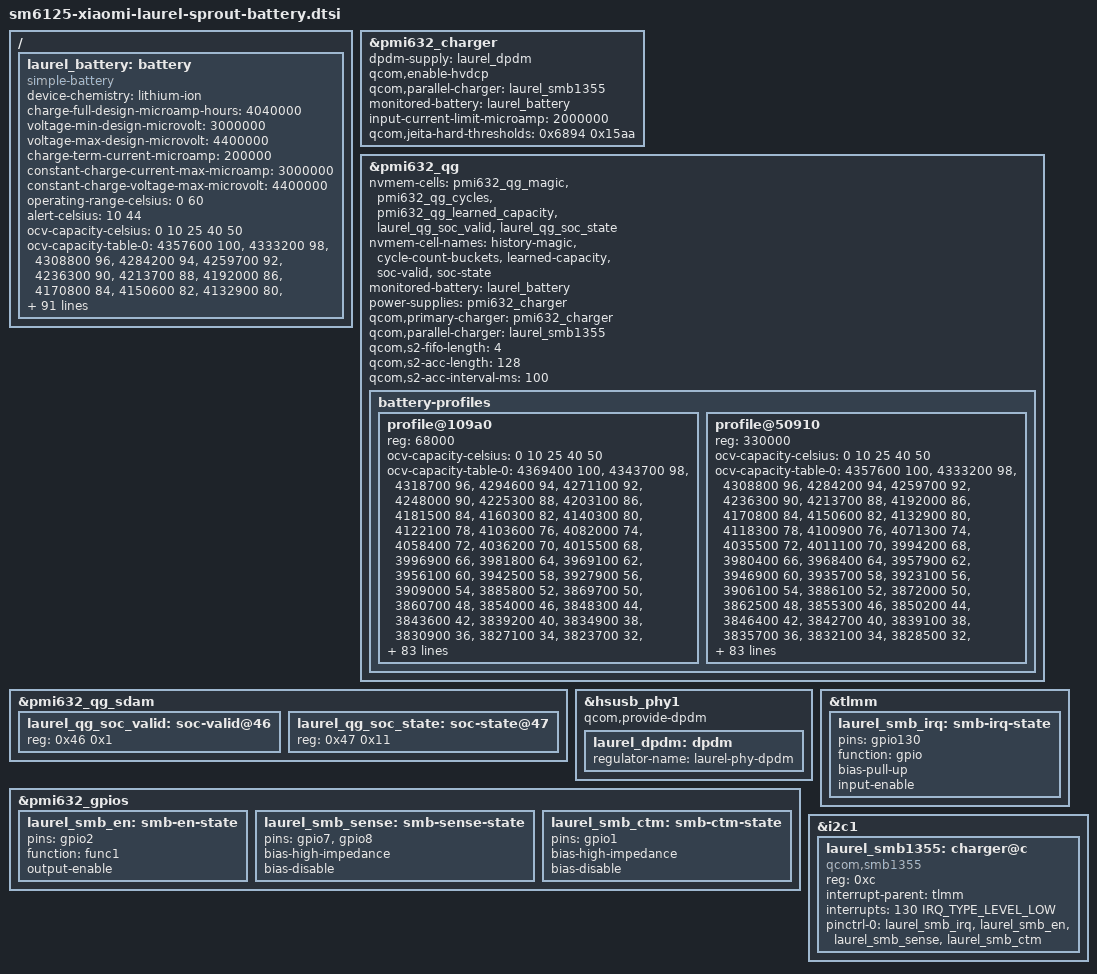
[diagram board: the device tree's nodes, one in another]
// SPDX-License-Identifier: GPL-2.0-only
/*
 * Derived from LineageOS android_kernel_xiaomi_sm6125, revision
 * 77d2912bc00eda19182a95a24bbe23543c792814, Laurel Wingtech fallback
 * battery profile. Original Qualcomm/Wingtech data, not generated curves.
 * See companion kernel Documentation/android/PMIC_BATTERY.md.
 */
/ {
	laurel_battery: battery {
		compatible = "simple-battery";
		device-chemistry = "lithium-ion";
		charge-full-design-microamp-hours = <4040000>;
		voltage-min-design-microvolt = <3000000>;
		voltage-max-design-microvolt = <4400000>;
		charge-term-current-microamp = <200000>;
		constant-charge-current-max-microamp = <3000000>;
		constant-charge-voltage-max-microvolt = <4400000>;
		operating-range-celsius = <0 60>;
		alert-celsius = <10 44>;
		ocv-capacity-celsius = <0 10 25 40 50>;
		/* Stock discharge OCV at 0 C. */
		ocv-capacity-table-0 = <4357600 100>,
			<4333200 98>,
			<4308800 96>,
			<4284200 94>,
			<4259700 92>,
			<4236300 90>,
			<4213700 88>,
			<4192000 86>,
			<4170800 84>,
			<4150600 82>,
			<4132900 80>,
			<4118300 78>,
			<4100900 76>,
			<4071300 74>,
			<4035500 72>,
			<4011100 70>,
			<3994200 68>,
			<3980400 66>,
			<3968400 64>,
			<3957900 62>,
			<3946900 60>,
			<3935700 58>,
			<3923100 56>,
			<3906100 54>,
			<3886100 52>,
			<3872000 50>,
			<3862500 48>,
			<3855300 46>,
			<3850200 44>,
			<3846400 42>,
			<3842700 40>,
			<3839100 38>,
			<3835700 36>,
			<3832100 34>,
			<3828500 32>,
			<3826500 30>,
			<3825900 28>,
			<3825400 26>,
			<3822400 24>,
			<3813100 22>,
			<3801800 20>,
			<3788500 18>,
			<3773200 16>,
			<3755800 14>,
			<3739300 12>,
			<3727700 10>,
			<3724200 9>,
			<3721100 8>,
			<3718300 7>,
			<3713700 6>,
			<3693100 5>,
			<3648900 4>,
			<3590700 3>,
			<3511800 2>,
			<3387200 1>,
			<3000000 0>;
		/* Stock discharge OCV at 10 C. */
		ocv-capacity-table-1 = <4371400 100>,
			<4347700 98>,
			<4321500 96>,
			<4295700 94>,
			<4271400 92>,
			<4247900 90>,
			<4225400 88>,
			<4203700 86>,
			<4182300 84>,
			<4160400 82>,
			<4139400 80>,
			<4121800 78>,
			<4106900 76>,
			<4087700 74>,
			<4055100 72>,
			<4021900 70>,
			<4003100 68>,
			<3989900 66>,
			<3977900 64>,
			<3967700 62>,
			<3956500 60>,
			<3936800 58>,
			<3908900 56>,
			<3889400 54>,
			<3877900 52>,
			<3869000 50>,
			<3861500 48>,
			<3855300 46>,
			<3849400 44>,
			<3843500 42>,
			<3838200 40>,
			<3833200 38>,
			<3828600 36>,
			<3824600 34>,
			<3821400 32>,
			<3818100 30>,
			<3815000 28>,
			<3811800 26>,
			<3806800 24>,
			<3797700 22>,
			<3786500 20>,
			<3774100 18>,
			<3759600 16>,
			<3742000 14>,
			<3729400 12>,
			<3720800 10>,
			<3717300 9>,
			<3715000 8>,
			<3712400 7>,
			<3708300 6>,
			<3686200 5>,
			<3642300 4>,
			<3584200 3>,
			<3504800 2>,
			<3380500 1>,
			<3000000 0>;
		/* Stock discharge OCV at 25 C. */
		ocv-capacity-table-2 = <4382500 100>,
			<4359800 98>,
			<4335600 96>,
			<4310700 94>,
			<4286000 92>,
			<4261900 90>,
			<4238200 88>,
			<4214800 86>,
			<4191800 84>,
			<4169400 82>,
			<4146800 80>,
			<4125600 78>,
			<4107900 76>,
			<4092200 74>,
			<4071100 72>,
			<4038700 70>,
			<4010300 68>,
			<3995800 66>,
			<3984800 64>,
			<3971800 62>,
			<3957300 60>,
			<3940500 58>,
			<3916700 56>,
			<3892200 54>,
			<3876900 52>,
			<3865800 50>,
			<3855900 48>,
			<3846400 46>,
			<3837900 44>,
			<3830400 42>,
			<3823900 40>,
			<3818200 38>,
			<3813300 36>,
			<3809000 34>,
			<3805400 32>,
			<3802000 30>,
			<3798500 28>,
			<3795000 26>,
			<3790400 24>,
			<3782500 22>,
			<3772100 20>,
			<3760500 18>,
			<3746900 16>,
			<3731100 14>,
			<3716600 12>,
			<3707100 10>,
			<3704400 9>,
			<3703100 8>,
			<3701500 7>,
			<3697200 6>,
			<3673900 5>,
			<3630600 4>,
			<3572600 3>,
			<3493400 2>,
			<3370200 1>,
			<3000000 0>;
		/* Stock discharge OCV at 40 C. */
		ocv-capacity-table-3 = <4385300 100>,
			<4361200 98>,
			<4337800 96>,
			<4314000 94>,
			<4289900 92>,
			<4266100 90>,
			<4242500 88>,
			<4219000 86>,
			<4195800 84>,
			<4172800 82>,
			<4149900 80>,
			<4127500 78>,
			<4106700 76>,
			<4087400 74>,
			<4067100 72>,
			<4043600 70>,
			<4020600 68>,
			<4003300 66>,
			<3988800 64>,
			<3973900 62>,
			<3958800 60>,
			<3942000 58>,
			<3919500 56>,
			<3894600 54>,
			<3877400 52>,
			<3865100 50>,
			<3854500 48>,
			<3844500 46>,
			<3835500 44>,
			<3827400 42>,
			<3820100 40>,
			<3813500 38>,
			<3807900 36>,
			<3802700 34>,
			<3798200 32>,
			<3794100 30>,
			<3789600 28>,
			<3785000 26>,
			<3779200 24>,
			<3771000 22>,
			<3760700 20>,
			<3749300 18>,
			<3736000 16>,
			<3720500 14>,
			<3706300 12>,
			<3697600 10>,
			<3695300 9>,
			<3693700 8>,
			<3692000 7>,
			<3687000 6>,
			<3662100 5>,
			<3618700 4>,
			<3561200 3>,
			<3482900 2>,
			<3362200 1>,
			<3000000 0>;
		/* Stock discharge OCV at 50 C. */
		ocv-capacity-table-4 = <4385700 100>,
			<4361300 98>,
			<4338200 96>,
			<4314900 94>,
			<4291300 92>,
			<4267800 90>,
			<4244300 88>,
			<4220900 86>,
			<4197700 84>,
			<4174600 82>,
			<4151700 80>,
			<4129300 78>,
			<4107300 76>,
			<4086000 74>,
			<4065200 72>,
			<4045000 70>,
			<4025500 68>,
			<4007300 66>,
			<3990100 64>,
			<3973600 62>,
			<3958600 60>,
			<3942600 58>,
			<3920800 56>,
			<3895700 54>,
			<3877800 52>,
			<3865400 50>,
			<3854600 48>,
			<3844300 46>,
			<3834900 44>,
			<3826400 42>,
			<3818900 40>,
			<3812100 38>,
			<3806100 36>,
			<3800500 34>,
			<3795100 32>,
			<3790000 30>,
			<3784600 28>,
			<3779200 26>,
			<3772600 24>,
			<3763900 22>,
			<3753300 20>,
			<3741700 18>,
			<3728600 16>,
			<3713200 14>,
			<3699200 12>,
			<3691700 10>,
			<3689300 9>,
			<3687400 8>,
			<3685900 7>,
			<3679800 6>,
			<3652700 5>,
			<3608600 4>,
			<3550800 3>,
			<3471400 2>,
			<3348700 1>,
			<3000000 0>;
	};
};

&pmi632_charger {
	dpdm-supply = <&laurel_dpdm>;
	qcom,enable-hvdcp;
	qcom,parallel-charger = <&laurel_smb1355>;
	status = "okay";
	monitored-battery = <&laurel_battery>;
	input-current-limit-microamp = <2000000>;
	/* Stock hard comparator codes: cold 0 C, hot 60 C. */
	qcom,jeita-hard-thresholds = <0x6894 0x15aa>;
};

&pmi632_qg {
	status = "okay";
	nvmem-cells = <&pmi632_qg_magic>, <&pmi632_qg_cycles>,
		      <&pmi632_qg_learned_capacity>, <&laurel_qg_soc_valid>,
		      <&laurel_qg_soc_state>;
	nvmem-cell-names = "history-magic", "cycle-count-buckets", "learned-capacity",
			   "soc-valid", "soc-state";
	monitored-battery = <&laurel_battery>;
	/* Optional secondary failure must not defer the battery gauge. The
	 * primary notifies after changing the secondary; QG reads that state.
	 */
	power-supplies = <&pmi632_charger>;
	qcom,primary-charger = <&pmi632_charger>;
	qcom,parallel-charger = <&laurel_smb1355>;
	qcom,s2-fifo-length = <4>;
	qcom,s2-acc-length = <128>;
	qcom,s2-acc-interval-ms = <100>;
};

&pmi632_qg_sdam {
	status = "okay";
	/delete-property/ read-only;
	/* LineageOS QG shutdown fields. Cycle/FCC/ESR/PBS cells stay untouched. */
	laurel_qg_soc_valid: soc-valid@46 {
		reg = <0x46 0x1>;
	};
	laurel_qg_soc_state: soc-state@47 {
		reg = <0x47 0x11>;
	};
};

/* Supplier OCV curves are selected by the physical 100k-pullup ID ADC. */
&pmi632_qg {
	battery-profiles {
		#address-cells = <1>;
		#size-cells = <0>;
		/* Stock Sunwoda profile, battery ID 68 kohm. */
		profile@109a0 {
			reg = <68000>;
			ocv-capacity-celsius = <0 10 25 40 50>;
			ocv-capacity-table-0 = <4369400 100>,
				<4343700 98>,
				<4318700 96>,
				<4294600 94>,
				<4271100 92>,
				<4248000 90>,
				<4225300 88>,
				<4203100 86>,
				<4181500 84>,
				<4160300 82>,
				<4140300 80>,
				<4122100 78>,
				<4103600 76>,
				<4082000 74>,
				<4058400 72>,
				<4036200 70>,
				<4015500 68>,
				<3996900 66>,
				<3981800 64>,
				<3969100 62>,
				<3956100 60>,
				<3942500 58>,
				<3927900 56>,
				<3909000 54>,
				<3885800 52>,
				<3869700 50>,
				<3860700 48>,
				<3854000 46>,
				<3848300 44>,
				<3843600 42>,
				<3839200 40>,
				<3834900 38>,
				<3830900 36>,
				<3827100 34>,
				<3823700 32>,
				<3820300 30>,
				<3817300 28>,
				<3814000 26>,
				<3808700 24>,
				<3800100 22>,
				<3789900 20>,
				<3778000 18>,
				<3764200 16>,
				<3748200 14>,
				<3733500 12>,
				<3724400 10>,
				<3721300 9>,
				<3719000 8>,
				<3717600 7>,
				<3714000 6>,
				<3690800 5>,
				<3646700 4>,
				<3589200 3>,
				<3510100 2>,
				<3385600 1>,
				<3000000 0>;
			ocv-capacity-table-1 = <4380600 100>,
				<4361600 98>,
				<4338000 96>,
				<4312900 94>,
				<4288200 92>,
				<4263100 90>,
				<4239600 88>,
				<4217400 86>,
				<4195500 84>,
				<4172900 82>,
				<4150400 80>,
				<4130100 78>,
				<4112200 76>,
				<4093300 74>,
				<4070700 72>,
				<4047300 70>,
				<4027000 68>,
				<4008700 66>,
				<3992100 64>,
				<3978600 62>,
				<3965100 60>,
				<3944800 58>,
				<3916500 56>,
				<3895400 54>,
				<3883200 52>,
				<3873800 50>,
				<3865200 48>,
				<3857700 46>,
				<3850500 44>,
				<3843400 42>,
				<3836900 40>,
				<3831200 38>,
				<3826100 36>,
				<3821500 34>,
				<3817700 32>,
				<3814000 30>,
				<3810400 28>,
				<3806800 26>,
				<3801500 24>,
				<3792900 22>,
				<3782300 20>,
				<3770800 18>,
				<3757400 16>,
				<3741200 14>,
				<3726400 12>,
				<3716700 10>,
				<3713900 9>,
				<3711800 8>,
				<3710400 7>,
				<3706400 6>,
				<3683400 5>,
				<3640100 4>,
				<3582400 3>,
				<3503400 2>,
				<3380000 1>,
				<3000000 0>;
			ocv-capacity-table-2 = <4385800 100>,
				<4363300 98>,
				<4340300 96>,
				<4316500 94>,
				<4293000 92>,
				<4269800 90>,
				<4246700 88>,
				<4223500 86>,
				<4200400 84>,
				<4177800 82>,
				<4155600 80>,
				<4134200 78>,
				<4113900 76>,
				<4094400 74>,
				<4074000 72>,
				<4052600 70>,
				<4032300 68>,
				<4013800 66>,
				<3996400 64>,
				<3980800 62>,
				<3966800 60>,
				<3950100 58>,
				<3924400 56>,
				<3899400 54>,
				<3884800 52>,
				<3874300 50>,
				<3864500 48>,
				<3854800 46>,
				<3845900 44>,
				<3837800 42>,
				<3830600 40>,
				<3824100 38>,
				<3818400 36>,
				<3813300 34>,
				<3809000 32>,
				<3805000 30>,
				<3800900 28>,
				<3797000 26>,
				<3791800 24>,
				<3783500 22>,
				<3772900 20>,
				<3761600 18>,
				<3748500 16>,
				<3732800 14>,
				<3718200 12>,
				<3708500 10>,
				<3705700 9>,
				<3704200 8>,
				<3702500 7>,
				<3697500 6>,
				<3673000 5>,
				<3629400 4>,
				<3571500 3>,
				<3492800 2>,
				<3368900 1>,
				<3000000 0>;
			ocv-capacity-table-3 = <4388400 100>,
				<4364000 98>,
				<4341600 96>,
				<4318900 94>,
				<4295900 92>,
				<4272600 90>,
				<4249300 88>,
				<4226100 86>,
				<4203200 84>,
				<4180600 82>,
				<4158100 80>,
				<4136100 78>,
				<4114900 76>,
				<4094800 74>,
				<4074600 72>,
				<4053800 70>,
				<4033900 68>,
				<4015800 66>,
				<3998900 64>,
				<3982600 62>,
				<3967500 60>,
				<3950700 58>,
				<3927400 56>,
				<3902800 54>,
				<3886600 52>,
				<3874900 50>,
				<3864300 48>,
				<3853800 46>,
				<3844300 44>,
				<3835700 42>,
				<3828000 40>,
				<3821000 38>,
				<3814700 36>,
				<3808800 34>,
				<3803700 32>,
				<3798800 30>,
				<3793800 28>,
				<3789000 26>,
				<3782900 24>,
				<3774000 22>,
				<3763100 20>,
				<3751600 18>,
				<3738700 16>,
				<3723400 14>,
				<3709200 12>,
				<3700200 10>,
				<3697700 9>,
				<3695800 8>,
				<3693800 7>,
				<3687500 6>,
				<3660300 5>,
				<3615900 4>,
				<3558000 3>,
				<3478700 2>,
				<3355100 1>,
				<3000000 0>;
			ocv-capacity-table-4 = <4388700 100>,
				<4363800 98>,
				<4341400 96>,
				<4319100 94>,
				<4296500 92>,
				<4273500 90>,
				<4250300 88>,
				<4227300 86>,
				<4204500 84>,
				<4181800 82>,
				<4159300 80>,
				<4137200 78>,
				<4115500 76>,
				<4094400 74>,
				<4073900 72>,
				<4053800 70>,
				<4034500 68>,
				<4016700 66>,
				<4000000 64>,
				<3983600 62>,
				<3968100 60>,
				<3951200 58>,
				<3928600 56>,
				<3904100 54>,
				<3887200 52>,
				<3875000 50>,
				<3864100 48>,
				<3853600 46>,
				<3844000 44>,
				<3835100 42>,
				<3827000 40>,
				<3819800 38>,
				<3813400 36>,
				<3807300 34>,
				<3801400 32>,
				<3795700 30>,
				<3789600 28>,
				<3783600 26>,
				<3776500 24>,
				<3767000 22>,
				<3755900 20>,
				<3744200 18>,
				<3731400 16>,
				<3715500 14>,
				<3701700 12>,
				<3694100 10>,
				<3691700 9>,
				<3689800 8>,
				<3687900 7>,
				<3680200 6>,
				<3650800 5>,
				<3606000 4>,
				<3548000 3>,
				<3468400 2>,
				<3344100 1>,
				<3000000 0>;
		};
		/* Stock Feimaotui profile, battery ID 330 kohm. */
		profile@50910 {
			reg = <330000>;
			ocv-capacity-celsius = <0 10 25 40 50>;
			ocv-capacity-table-0 = <4357600 100>,
				<4333200 98>,
				<4308800 96>,
				<4284200 94>,
				<4259700 92>,
				<4236300 90>,
				<4213700 88>,
				<4192000 86>,
				<4170800 84>,
				<4150600 82>,
				<4132900 80>,
				<4118300 78>,
				<4100900 76>,
				<4071300 74>,
				<4035500 72>,
				<4011100 70>,
				<3994200 68>,
				<3980400 66>,
				<3968400 64>,
				<3957900 62>,
				<3946900 60>,
				<3935700 58>,
				<3923100 56>,
				<3906100 54>,
				<3886100 52>,
				<3872000 50>,
				<3862500 48>,
				<3855300 46>,
				<3850200 44>,
				<3846400 42>,
				<3842700 40>,
				<3839100 38>,
				<3835700 36>,
				<3832100 34>,
				<3828500 32>,
				<3826500 30>,
				<3825900 28>,
				<3825400 26>,
				<3822400 24>,
				<3813100 22>,
				<3801800 20>,
				<3788500 18>,
				<3773200 16>,
				<3755800 14>,
				<3739300 12>,
				<3727700 10>,
				<3724200 9>,
				<3721100 8>,
				<3718300 7>,
				<3713700 6>,
				<3693100 5>,
				<3648900 4>,
				<3590700 3>,
				<3511800 2>,
				<3387200 1>,
				<3000000 0>;
			ocv-capacity-table-1 = <4371400 100>,
				<4347700 98>,
				<4321500 96>,
				<4295700 94>,
				<4271400 92>,
				<4247900 90>,
				<4225400 88>,
				<4203700 86>,
				<4182300 84>,
				<4160400 82>,
				<4139400 80>,
				<4121800 78>,
				<4106900 76>,
				<4087700 74>,
				<4055100 72>,
				<4021900 70>,
				<4003100 68>,
				<3989900 66>,
				<3977900 64>,
				<3967700 62>,
				<3956500 60>,
				<3936800 58>,
				<3908900 56>,
				<3889400 54>,
				<3877900 52>,
				<3869000 50>,
				<3861500 48>,
				<3855300 46>,
				<3849400 44>,
				<3843500 42>,
				<3838200 40>,
				<3833200 38>,
				<3828600 36>,
				<3824600 34>,
				<3821400 32>,
				<3818100 30>,
				<3815000 28>,
				<3811800 26>,
				<3806800 24>,
				<3797700 22>,
				<3786500 20>,
				<3774100 18>,
				<3759600 16>,
				<3742000 14>,
				<3729400 12>,
				<3720800 10>,
				<3717300 9>,
				<3715000 8>,
				<3712400 7>,
				<3708300 6>,
				<3686200 5>,
				<3642300 4>,
				<3584200 3>,
				<3504800 2>,
				<3380500 1>,
				<3000000 0>;
			ocv-capacity-table-2 = <4382500 100>,
				<4359800 98>,
				<4335600 96>,
				<4310700 94>,
				<4286000 92>,
				<4261900 90>,
				<4238200 88>,
				<4214800 86>,
				<4191800 84>,
				<4169400 82>,
				<4146800 80>,
				<4125600 78>,
				<4107900 76>,
				<4092200 74>,
				<4071100 72>,
				<4038700 70>,
				<4010300 68>,
				<3995800 66>,
				<3984800 64>,
				<3971800 62>,
				<3957300 60>,
				<3940500 58>,
				<3916700 56>,
				<3892200 54>,
				<3876900 52>,
				<3865800 50>,
				<3855900 48>,
				<3846400 46>,
				<3837900 44>,
				<3830400 42>,
				<3823900 40>,
				<3818200 38>,
				<3813300 36>,
				<3809000 34>,
				<3805400 32>,
				<3802000 30>,
				<3798500 28>,
				<3795000 26>,
				<3790400 24>,
				<3782500 22>,
				<3772100 20>,
				<3760500 18>,
				<3746900 16>,
				<3731100 14>,
				<3716600 12>,
				<3707100 10>,
				<3704400 9>,
				<3703100 8>,
				<3701500 7>,
				<3697200 6>,
				<3673900 5>,
				<3630600 4>,
				<3572600 3>,
				<3493400 2>,
				<3370200 1>,
				<3000000 0>;
			ocv-capacity-table-3 = <4385300 100>,
				<4361200 98>,
				<4337800 96>,
				<4314000 94>,
				<4289900 92>,
				<4266100 90>,
				<4242500 88>,
				<4219000 86>,
				<4195800 84>,
				<4172800 82>,
				<4149900 80>,
				<4127500 78>,
				<4106700 76>,
				<4087400 74>,
				<4067100 72>,
				<4043600 70>,
				<4020600 68>,
				<4003300 66>,
				<3988800 64>,
				<3973900 62>,
				<3958800 60>,
				<3942000 58>,
				<3919500 56>,
				<3894600 54>,
				<3877400 52>,
				<3865100 50>,
				<3854500 48>,
				<3844500 46>,
				<3835500 44>,
				<3827400 42>,
				<3820100 40>,
				<3813500 38>,
				<3807900 36>,
				<3802700 34>,
				<3798200 32>,
				<3794100 30>,
				<3789600 28>,
				<3785000 26>,
				<3779200 24>,
				<3771000 22>,
				<3760700 20>,
				<3749300 18>,
				<3736000 16>,
				<3720500 14>,
				<3706300 12>,
				<3697600 10>,
				<3695300 9>,
				<3693700 8>,
				<3692000 7>,
				<3687000 6>,
				<3662100 5>,
				<3618700 4>,
				<3561200 3>,
				<3482900 2>,
				<3362200 1>,
				<3000000 0>;
			ocv-capacity-table-4 = <4385700 100>,
				<4361300 98>,
				<4338200 96>,
				<4314900 94>,
				<4291300 92>,
				<4267800 90>,
				<4244300 88>,
				<4220900 86>,
				<4197700 84>,
				<4174600 82>,
				<4151700 80>,
				<4129300 78>,
				<4107300 76>,
				<4086000 74>,
				<4065200 72>,
				<4045000 70>,
				<4025500 68>,
				<4007300 66>,
				<3990100 64>,
				<3973600 62>,
				<3958600 60>,
				<3942600 58>,
				<3920800 56>,
				<3895700 54>,
				<3877800 52>,
				<3865400 50>,
				<3854600 48>,
				<3844300 46>,
				<3834900 44>,
				<3826400 42>,
				<3818900 40>,
				<3812100 38>,
				<3806100 36>,
				<3800500 34>,
				<3795100 32>,
				<3790000 30>,
				<3784600 28>,
				<3779200 26>,
				<3772600 24>,
				<3763900 22>,
				<3753300 20>,
				<3741700 18>,
				<3728600 16>,
				<3713200 14>,
				<3699200 12>,
				<3691700 10>,
				<3689300 9>,
				<3687400 8>,
				<3685900 7>,
				<3679800 6>,
				<3652700 5>,
				<3608600 4>,
				<3550800 3>,
				<3471400 2>,
				<3348700 1>,
				<3000000 0>;
		};
	};
};

/* Stock Laurel SMB1355: QUP SE1, address 0x0c, TLMM130 active-low IRQ. */
&hsusb_phy1 {
	qcom,provide-dpdm;
	laurel_dpdm: dpdm {
		regulator-name = "laurel-phy-dpdm";
	};
};

&pmi632_gpios {
	laurel_smb_en: smb-en-state {
		pins = "gpio2";
		function = "func1";
		output-enable;
	};
	laurel_smb_sense: smb-sense-state {
		pins = "gpio7", "gpio8";
		bias-high-impedance;
		bias-disable;
	};
	laurel_smb_ctm: smb-ctm-state {
		pins = "gpio1";
		bias-high-impedance;
		bias-disable;
	};
};

&tlmm {
	laurel_smb_irq: smb-irq-state {
		pins = "gpio130";
		function = "gpio";
		bias-pull-up;
		input-enable;
	};
};

&i2c1 {
	status = "okay";
	laurel_smb1355: charger@c {
		compatible = "qcom,smb1355";
		reg = <0xc>;
		interrupt-parent = <&tlmm>;
		interrupts = <130 IRQ_TYPE_LEVEL_LOW>;
		pinctrl-names = "default";
		pinctrl-0 = <&laurel_smb_irq &laurel_smb_en &laurel_smb_sense &laurel_smb_ctm>;
	};
};
